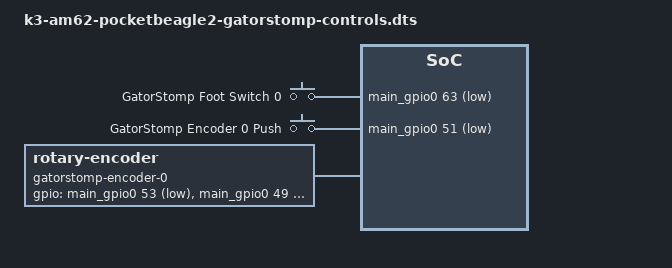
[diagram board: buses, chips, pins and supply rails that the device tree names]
// GatorStomp pedal controls on the PocketBeagle 2
//
// Foot switch 0: P2.22 (GPIO0_63) and GND
// Encoder 0 A: P2.18 (GPIO0_53)
// Encoder 0 B: P2.20 (GPIO0_49)
// Encoder 0 C: GND
// Encoder 0 push: P2.24 (GPIO0_51) and GND
//
// Every pin uses the internal pull up, so it reads low while its contact is closed.
// The gpio-keys driver turns the foot switch and the encoder push into input events.
//
// The rotary-encoder node turns encoder clicks into input events on kernels that have
// the rotary-encoder driver. On kernels without it, such as the BeagleBoard Debian image,
// the node is left unused and A and B stay free for user space to read with gpiod.
// pedal_sender.py checks which case it is in and handles both.

/dts-v1/;
/plugin/;

&{/chosen} {
	overlays {
		gatorstomp-controls = "GatorStomp foot switch and encoder";
	};
};

&main_pmx0 {
	gatorstomp_control_pins: gatorstomp-control-pins {
		// Input, pull up, Schmitt trigger, mode 7 (GPIO) for each pin
		pinctrl-single,pins = <
			// P2.22 GPIO0_63 foot switch 0
			0x100 0x64007
			// P2.18 GPIO0_53 encoder 0 A
			0x0d8 0x64007
			// P2.20 GPIO0_49 encoder 0 B
			0x0c8 0x64007
			// P2.24 GPIO0_51 encoder 0 push
			0x0d0 0x64007
		>;
	};
};

&{/} {
	gatorstomp-controls {
		compatible = "gpio-keys";
		// This node applies the pin settings for all the controls, including encoder A and B,
		// so the pull ups are set even on kernels without the rotary-encoder driver
		pinctrl-names = "default";
		pinctrl-0 = <&gatorstomp_control_pins>;

		footswitch-0 {
			label = "GatorStomp Foot Switch 0";
			// BTN_0
			linux,code = <0x100>;
			// GPIO0_63, active low
			gpios = <&main_gpio0 63 1>;
			debounce-interval = <10>;
		};

		encoder-0-push {
			label = "GatorStomp Encoder 0 Push";
			// BTN_TRIGGER_HAPPY1
			linux,code = <0x2c0>;
			// GPIO0_51, active low
			gpios = <&main_gpio0 51 1>;
			debounce-interval = <10>;
		};
	};

	gatorstomp-encoder-0 {
		compatible = "rotary-encoder";
		// A (GPIO0_53) then B (GPIO0_49), both active low. In this order clockwise is +1.
		gpios = <&main_gpio0 53 1>, <&main_gpio0 49 1>;
		// Report clicks as relative steps on REL_DIAL
		linux,axis = <0x07>;
		rotary-encoder,relative-axis;
		// One click is one full cycle of A and B (20 clicks and 20 pulses per turn)
		rotary-encoder,steps-per-period = <1>;
	};
};
